# STM32H573 register map
File version: 1.8
CPU: CM33 r0p0, little endian, MPU, FPU, 4 interrupt priority bits
Registers are 32-bit, read-write, reset 0x0 unless marked. A register's access mark holds for its fields unless they carry their own. Offsets are from the block's base; [hi:lo] are bit positions; {n}, {i} and the like mark numbered series; 'fields as' and 'values as' point back to an identical list.

## TIM1 — Advanced-control timers
Base 0x40012C00
Same registers: SEC_TIM1 0x50012C00
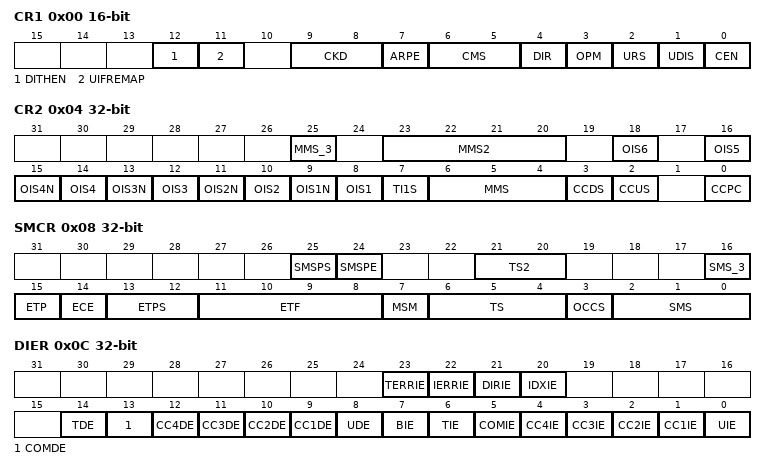
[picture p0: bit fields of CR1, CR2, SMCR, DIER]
0x00 CR1 16-bit — TIM1 control register 1
  [12] DITHEN — Dithering enable Note: The DITHEN bit can only be modified when CEN bit is reset.
    0=Disabled (Dithering disabled); 1=Enabled (Dithering enabled)
  [11] UIFREMAP — UIF status bit remapping
    0=Disabled (No remapping. UIF status bit is not copied to TIMx_CNT register bit 31); 1=Enabled (Remapping enabled. UIF status bit is copied to TIMx_CNT register bit 31)
  [9:8] CKD — Clock division This bit-field indicates the division ratio between the timer clock (tim_ker_ck) frequency and the dead-time and sampling clock (t sub DTS /sub )used by the dead-time generators and the digital filters (tim_etr_in, tim_tix),
    0=Div1 (t_DTS = t_CK_INT); 1=Div2 (t_DTS = 2 × t_CK_INT); 2=Div4 (t_DTS = 4 × t_CK_INT)
  [7] ARPE — Auto-reload preload enable
    0=Disabled (TIMx_APRR register is not buffered); 1=Enabled (TIMx_APRR register is buffered)
  [6:5] CMS — Center-aligned mode selection Note: It is not allowed to switch from edge-aligned mode to center-aligned mode as long as the counter is enabled (CEN=1)
    0=EdgeAligned (The counter counts up or down depending on the direction bit); 1=CenterAligned1 (The counter counts up and down alternatively. Output compare interrupt flags are set only when the counter is counting down.); 2=CenterAligned2 (The counter counts up and down alternatively. Output compare interrupt flags are set only when the counter is counting up.); 3=CenterAligned3 (The counter counts up and down alternatively. Output compare interrupt flags are set both when the counter is counting up or down.)
  [4] DIR — Direction Note: This bit is read only when the timer is configured in Center-aligned mode or Encoder mode.
    0=Up (Counter used as upcounter); 1=Down (Counter used as downcounter)
  [3] OPM — One-pulse mode
    0=Disabled (Counter is not stopped at update event); 1=Enabled (Counter stops counting at the next update event (clearing the CEN bit))
  [2] URS — Update request source This bit is set and cleared by software to select the UEV event sources. Counter overflow/underflow Setting the UG bit Update generation through the slave mode controller
    0=AnyEvent (Any of counter overflow/underflow, setting UG, or update through slave mode, generates an update interrupt or DMA request); 1=CounterOnly (Only counter overflow/underflow generates an update interrupt or DMA request)
  [1] UDIS — Update disable This bit is set and cleared by software to enable/disable UEV event generation. Counter overflow/underflow Setting the UG bit Update generation through the slave mode controller Buffered registers are then loaded with their preload values.
    0=Enabled (Update event enabled); 1=Disabled (Update event disabled)
  [0] CEN — Counter enable Note: External clock, gated mode and encoder mode can work only if the CEN bit has been previously set by software. However trigger mode can set the CEN bit automatically by hardware.
    0=Disabled (Counter disabled); 1=Enabled (Counter enabled)
0x04 CR2 — TIM1 control register 2
  [25] MMS_3
  [23:20] MMS2 — Master mode selection 2 These bits allow the information to be sent to ADC for synchronization (tim_trgo2) to be selected. The combination is as follows: Note: The clock of the slave timer or ADC must be enabled prior to receive events from the master timer, and must not be changed on-the-fly while triggers are received from the master timer.
  [2n+7] OIS{n}N (n=1..4) — Output Idle state (OC{n}N output)
    0=Reset (OCxN=0 after a dead-time when MOE=0); 1=Set (OCxN=1 after a dead-time when MOE=0)
  [2n+6] OIS{n} (n=1..6) — Output Idle state (OC{n} output)
    0=Reset (OCx=0 (after a dead-time if OCx(N) is implemented) when MOE=0); 1=Set (OCx=1 (after a dead-time if OCx(N) is implemented) when MOE=0)
  [7] TI1S — tim_ti1 selection
    0=Normal (The TIMx_CH1 pin is connected to TI1 input); 1=XOR (The TIMx_CH1, CH2, CH3 pins are connected to TI1 input)
  [6:4] MMS — MMS[2:0]: Master mode selection These bits select the information to be sent in master mode to slave timers for synchronization (tim_trgo). The combination is as follows: Other codes reserved Note: The clock of the slave timer or ADC must be enabled prior to receive events from the master timer, and must not be changed on-the-fly while triggers are received from the master timer.
  [3] CCDS — Capture/compare DMA selection
    0=OnCompare (CCx DMA request sent when CCx event occurs); 1=OnUpdate (CCx DMA request sent when update event occurs)
  [2] CCUS — Capture/compare control update selection Note: This bit acts only on channels that have a complementary output.
    0=Sw (When capture/compare control bits are preloaded (CCPC=1), they are updated by setting the COMG bit only); 1=SwOrEdge (When capture/compare control bits are preloaded (CCPC=1), they are updated by setting the COMG bit or when an rising edge occurs on TRGI)
  [0] CCPC — Capture/compare preloaded control Note: This bit acts only on channels that have a complementary output.
    0=NotPreloaded (CCxE, CCxNE and OCxM bits are not preloaded); 1=Preloaded (CCxE, CCxNE and OCxM bits are preloaded)
0x08 SMCR — TIM1 slave mode control register
  [25] SMSPS — SMS preload source This bit selects whether the events that triggers the SMS[3:0] bitfield transfer from preload to active
    0=Update (SMSM[3:0] is preloaded from Update event); 1=Index (SMSM[3:0] is preloaded from Index event)
  [24] SMSPE — SMS preload enable This bit selects whether the SMS[3:0] bitfield is preloaded
    0=NotPreloaded (SMSM[3:0] is not preloaded); 1=PreloadEnabled (SMSM[3:0] is preload is enabled)
  [21:20] TS2 — Trigger selection This bit-field selects the trigger input to be used to synchronize the counter. Others: Reserved See for product specific implementation details. Note: These bits must be changed only when they are not used (e.g. when SMS=000) to avoid wrong edge detections at the transition.
  [16] SMS_3 — Slave mode selection When external signals are selected the active edge of the trigger signal (tim_trgi) is linked to the polarity selected on the external input (see Input Control register and Control Register description. Note: The gated mode must not be used if tim_ti1f_ed is selected as the trigger input (TS=00100). Indeed, tim_ti1f_ed outputs 1 pulse for each transition on tim_ti1f, whereas the gated mode checks the level of the trigger signal. Note: The clock of the slave peripherals (timer, ADC, ...) receiving the tim_trgo signal must be enabled prior to receive events from the master timer, and the clock frequency (prescaler) must not be changed on-the-fly while triggers are received from the master timer.
  [15] ETP — External trigger polarity This bit selects whether tim_etr_in or tim_etr_in is used for trigger operations
    0=NotInverted (ETR is noninverted, active at high level or rising edge); 1=Inverted (ETR is inverted, active at low level or falling edge)
  [14] ECE — External clock enable This bit enables External clock mode 2. Note: Setting the ECE bit has the same effect as selecting external clock mode 1 with tim_trgi connected to tim_etrf (SMS=111 and TS=00111). It is possible to simultaneously use external clock mode 2 with the following slave modes: reset mode, gated mode and trigger mode. Nevertheless, tim_trgi must not be connected to tim_etrf in this case (TS bits must not be 00111). Note: If external clock mode 1 and external clock mode 2 are enabled at the same time, the external clock input is tim_etrf.
    0=Disabled (External clock mode 2 disabled); 1=Enabled (External clock mode 2 enabled. The counter is clocked by any active edge on the ETRF signal.)
  [13:12] ETPS — External trigger prescaler External trigger signal tim_etrp frequency must be at most 1/4 of TIMxCLK frequency. A prescaler can be enabled to reduce tim_etrp frequency. It is useful when inputting fast external clocks on tim_etr_in.
    0=Div1 (Prescaler OFF); 1=Div2 (ETRP frequency divided by 2); 2=Div4 (ETRP frequency divided by 4); 3=Div8 (ETRP frequency divided by 8)
  [11:8] ETF — External trigger filter This bit-field then defines the frequency used to sample tim_etrp signal and the length of the digital filter applied to tim_etrp. The digital filter is made of an event counter in which N consecutive events are needed to validate a transition on the output:
    0=No filter, sampling is done at fDTS; 1=FCK_INT_N2 (fSAMPLING=fCK_INT, N=2); 2=FCK_INT_N4 (fSAMPLING=fCK_INT, N=4); 3=FCK_INT_N8 (fSAMPLING=fCK_INT, N=8); 4=FDTS_Div2_N6 (fSAMPLING=fDTS/2, N=6); 5=FDTS_Div2_N8 (fSAMPLING=fDTS/2, N=8); 6=FDTS_Div4_N6 (fSAMPLING=fDTS/4, N=6); 7=FDTS_Div4_N8 (fSAMPLING=fDTS/4, N=8); 8=FDTS_Div8_N6 (fSAMPLING=fDTS/8, N=6); 9=FDTS_Div8_N8 (fSAMPLING=fDTS/8, N=8); 10=FDTS_Div16_N5 (fSAMPLING=fDTS/16, N=5); 11=FDTS_Div16_N6 (fSAMPLING=fDTS/16, N=6); 12=FDTS_Div16_N8 (fSAMPLING=fDTS/16, N=8); 13=FDTS_Div32_N5 (fSAMPLING=fDTS/32, N=5); 14=FDTS_Div32_N6 (fSAMPLING=fDTS/32, N=6); 15=FDTS_Div32_N8 (fSAMPLING=fDTS/32, N=8)
  [7] MSM — Master/slave mode
    0=NoSync (No action); 1=Sync (The effect of an event on the trigger input (TRGI) is delayed to allow a perfect synchronization between the current timer and its slaves (through TRGO). It is useful if we want to synchronize several timers on a single external event.)
  [6:4] TS — TS[2:0]: Trigger selection This bitfield is combined with TS[4:3] bits. This bit-field selects the trigger input to be used to synchronize the counter. Others: Reserved See Table 605: TIMx internal trigger connection for more details on tim_itrx meaning for each Timer. Note: These bits must be changed only when they are not used (e.g. when SMS=000) to avoid wrong edge detections at the transition.
  [3] OCCS — OCREF clear selection This bit is used to select the OCREF clear source.
  [2:0] SMS — SMS[2:0]: Slave mode selection When external signals are selected the active edge of the trigger signal (tim_trgi) is linked to the polarity selected on the external input (see Input Control register and Control Register description. Note: The gated mode must not be used if tim_ti1f_ed is selected as the trigger input (TS=00100). Indeed, tim_ti1f_ed outputs 1 pulse for each transition on TI1F, whereas the gated mode checks the level of the trigger signal. Note: The clock of the slave peripherals (timer, ADC, ...) receiving the tim_trgo or the tim_trgo2 signals must be enabled prior to receive events from the master timer, and the clock frequency (prescaler) must not be changed on-the-fly while triggers are received from the master timer.
0x0C DIER — TIM1 DMA/interrupt enable register
  [23] TERRIE — Transition error interrupt enable
    0=Disabled (Transition error interrupt disabled); 1=Enabled (Transition error interrupt enabled)
  [22] IERRIE — Index error interrupt enable
    0=Disabled (Index error interrupt disabled); 1=Enabled (Index error interrupt enabled)
  [21] DIRIE — Direction change interrupt enable
    0=Disabled (Direction change interrupt disabled); 1=Enabled (Direction change interrupt enabled)
  [20] IDXIE — Index interrupt enable
    0=Disabled (Index change interrupt disabled); 1=Enabled (Index change interrupt enabled)
  [14] TDE — Trigger DMA request enable
    0=Disabled (Trigger DMA request disabled); 1=Enabled (Trigger DMA request enabled)
  [13] COMDE — COM DMA request enable
    0=Disabled (COM DMA request disabled); 1=Enabled (COM DMA request enabled)
  [n+8] CC{n}DE (n=1..4) — Capture/Compare {n} DMA request enable
    0=Disabled (CCx DMA request disabled); 1=Enabled (CCx DMA request enabled)
  [8] UDE — Update DMA request enable
    0=Disabled (Update DMA request disabled); 1=Enabled (Update DMA request enabled)
  [7] BIE — Break interrupt enable
    0=Disabled (Break interrupt disabled); 1=Enabled (Break interrupt enabled)
  [6] TIE — Trigger interrupt enable
    0=Disabled (Trigger interrupt disabled); 1=Enabled (Trigger interrupt enabled)
  [5] COMIE — COM interrupt enable
    0=Disabled (COM interrupt disabled); 1=Enabled (COM interrupt enabled)
  [n] CC{n}IE (n=1..4) — Capture/Compare {n} interrupt enable
    0=Disabled (CCx interrupt disabled); 1=Enabled (CCx interrupt enabled)
  [0] UIE — Update interrupt enable
    0=Disabled (Update interrupt disabled); 1=Enabled (Update interrupt enabled)
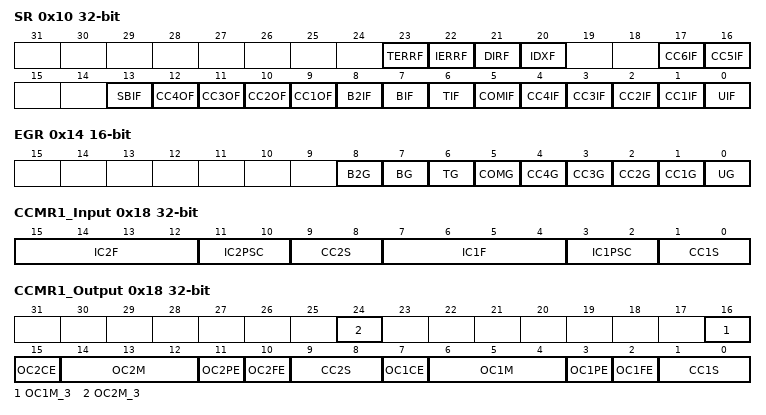
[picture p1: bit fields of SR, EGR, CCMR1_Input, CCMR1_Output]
0x10 SR — TIM1 status register
  [23] TERRF write-0-clears — Transition error interrupt flag This flag is set by hardware when a transition error is detected in encoder mode. It is cleared by software by writing it to '0'.
    on read: 0=NoTrigger (No encoder transition error has been detected); 1=Trigger (An encoder transition error has been detected) | on write: 0=Clear flag
  [22] IERRF write-0-clears — Index error interrupt flag This flag is set by hardware when an index error is detected. It is cleared by software by writing it to '0'.
    on read: 0=NoTrigger (No index error has been detected); 1=Trigger (An index erorr has been detected) | on write: 0=Clear flag
  [21] DIRF write-0-clears — Direction change interrupt flag This flag is set by hardware when the direction changes in encoder mode (DIR bit value in TIMx_CR is changing). It is cleared by software by writing it to '0'.
    on read: 0=NoTrigger (No direction change has been detected); 1=Trigger (A direction change has been detected) | on write: 0=Clear flag
  [20] IDXF write-0-clears — Index interrupt flag This flag is set by hardware when an index event is detected. It is cleared by software by writing it to '0'.
    on read: 0=NoTrigger (No index event occurred); 1=Trigger (An index event has occurred) | on write: 0=Clear flag
  [17] CC6IF write-0-clears — Compare 6 interrupt flag Refer to CC1IF description Note: Channel 6 can only be configured as output.
    on read: 0=NoMatch (No campture/compare has been detected); 1=Match (If CC1 is an output: The content of the counter TIMx_CNT matches the content of the TIMx_CCR1 register. If CC1 is an input: The counter value has been captured in TIMx_CCR1 register.) | on write: 0=Clear flag
  [16] CC5IF write-0-clears — Compare 5 interrupt flag Refer to CC1IF description Note: Channel 5 can only be configured as output.
    values as CC6IF
  [13] SBIF write-0-clears — System break interrupt flag This flag is set by hardware as soon as the system break input goes active. It can be cleared by software if the system break input is not active. This flag must be reset to re-start PWM operation.
    on read: 0=NoTrigger (No break event occurred); 1=Trigger (An active level has been detected on the system break input. An interrupt is generated if BIE=1 in the TIMx_DIER register) | on write: 0=Clear flag
  [n+8] CC{n}OF (n=1..4) write-0-clears — Capture/Compare {n} overcapture flag
    on read: 0=No overcapture has been detected; 1=Overcapture (The counter value has been captured in TIMx_CCRx register while CCxIF flag was already set) | on write: 0=Clear flag
  [8] B2IF write-0-clears — Break 2 interrupt flag This flag is set by hardware as soon as the break 2 input goes active. It can be cleared by software if the break 2 input is not active.
    on read: 0=NoTrigger (No break event occurred); 1=Trigger (An active level has been detected on the break 2 input. An interrupt is generated if BIE=1 in the TIMx_DIER register) | on write: 0=Clear flag
  [7] BIF write-0-clears — Break interrupt flag This flag is set by hardware as soon as the break input goes active. It can be cleared by software if the break input is not active.
    on read: 0=NoTrigger (No break event occurred); 1=Trigger (An active level has been detected on the break input. An interrupt is generated if BIE=1 in the TIMx_DIER register) | on write: 0=Clear flag
  [6] TIF write-0-clears — Trigger interrupt flag This flag is set by hardware on the TRG trigger event (active edge detected on tim_trgi input when the slave mode controller is enabled in all modes but gated mode. It is set when the counter starts or stops when gated mode is selected. It is cleared by software.
    on read: 0=No trigger event occurred; 1=Trigger interrupt pending | on write: 0=Clear flag
  [5] COMIF write-0-clears — COM interrupt flag This flag is set by hardware on COM event (when capture/compare Control bits CCxE, CCxNE, OCxM have been updated). It is cleared by software.
    on read: 0=No COM event occurred; 1=COM (COM interrupt pending) | on write: 0=Clear flag
  [n] CC{n}IF (n=1..4) write-0-clears — Capture/compare {n} interrupt flag
    values as CC6IF
  [0] UIF write-0-clears — Update interrupt flag This bit is set by hardware on an update event. It is cleared by software. At overflow or underflow regarding the repetition counter value (update if repetition counter = 0) and if the UDIS=0 in the TIMx_CR1 register. When CNT is reinitialized by software using the UG bit in TIMx_EGR register, if URS=0 and UDIS=0 in the TIMx_CR1 register. When CNT is reinitialized by a trigger event (refer to Section 65.6.3: TIM1 slave mode control register (TIM1_SMCR)), if URS=0 and UDIS=0 in the TIMx_CR1 register.
    on read: 0=NoUpdateOccurred; 1=UpdatePending (Update interrupt pending) | on write: 0=Clear flag
0x14 EGR 16-bit wo — TIM1 event generation register
  [8] B2G — Break 2 generation This bit is set by software in order to generate an event, it is automatically cleared by hardware.
    1=Trigger (A break 2 event is generated. MOE bit is cleared and B2IF flag is set. Related interrupt can occur if enabled)
  [7] BG — Break generation This bit is set by software in order to generate an event, it is automatically cleared by hardware.
    1=Trigger (A break event is generated. MOE bit is cleared and BIF flag is set. Related interrupt or DMA transfer can occur if enabled)
  [6] TG — Trigger generation This bit is set by software in order to generate an event, it is automatically cleared by hardware.
    1=Trigger (The TIF flag is set in TIMx_SR register. Related interrupt or DMA transfer can occur if enabled.)
  [5] COMG — Capture/compare control update generation This bit can be set by software, it is automatically cleared by hardware Note: This bit acts only on channels having a complementary output.
    1=Trigger (When CCPC bit is set, it allows CCxE, CCxNE and OCxM bits to be updated)
  [n] CC{n}G (n=1..4) — Capture/compare {n} generation
    1=Trigger (If CC1 is an output: CC1IF flag is set, Corresponding interrupt or DMA request is sent if enabled. If CC1 is an input: The current value of the counter is captured in TIMx_CCR1 register.)
  [0] UG — Update generation This bit can be set by software, it is automatically cleared by hardware.
    1=Update (Re-initializes the timer counter and generates an update of the registers.)
0x18 CCMR1_Input — TIM1 capture/compare mode register 1 [alternate]
  [9:8] CC2S — Capture/compare 2 selection This bit-field defines the direction of the channel (input/output) as well as the used input. Note: CC2S bits are writable only when the channel is OFF (CC2E = '0' in TIMx_CCER).
    1=TI2 (CC2 channel is configured as input, IC2 is mapped on TI2); 2=TI1 (CC2 channel is configured as input, IC2 is mapped on TI1); 3=TRC (CC2 channel is configured as input, IC2 is mapped on TRC)
  [8n-1:8n-4] IC{n}F (n=1..2) — Input capture {n} filter
    values as SMCR.ETF
  [8n-5:8n-6] IC{n}PSC (n=1..2) — Input capture {n} prescaler
    0=No prescaler, capture is done each time an edge is detected on the capture input; 1=TwoEvents (Capture is done once every 2 events); 2=FourEvents (Capture is done once every 4 events); 3=EightEvents (Capture is done once every 8 events)
  [1:0] CC1S — Capture/compare 1 Selection This bit-field defines the direction of the channel (input/output) as well as the used input. Note: CC1S bits are writable only when the channel is OFF (CC1E = '0' in TIMx_CCER).
    1=TI1 (CC1 channel is configured as input, IC1 is mapped on TI1); 2=TI2 (CC1 channel is configured as input, IC1 is mapped on TI2); 3=TRC (CC1 channel is configured as input, IC1 is mapped on TRC)
0x18 CCMR1_Output (alternate view of CCMR1_Input) — TIM1 capture/compare mode register 1 [alternate]
  [8n+8] OC{n}M_3 (n=1..2) — Output compare {n} mode, bit 3
    0=Normal output compare mode (modes 0-7); 1=Extended output compare mode (modes 7-15)
  [8n-1] OC{n}CE (n=1..2) — Output compare {n} clear enable
    0=Disabled (OCxRef is not affected by the ocref_clr_int signal); 1=Enabled (OCxRef is cleared as soon as a High level is detected on ocref_clr_int signal)
  [8n-2:8n-4] OC{n}M (n=1..2) — Output compare {n} mode
    0=Frozen (The comparison between the output compare register TIMx_CCRy and the counter TIMx_CNT has no effect on the outputs / OpmMode1: Retriggerable OPM mode 1 - In up-counting mode, the channel is active until a trigger event is detected (on TRGI signal). In down-counting mode, the channel is inactive); 1=ActiveOnMatch (Set channel to active level on match. OCyREF signal is forced high when the counter matches the capture/compare register / OpmMode2: Inversely to OpmMode1); 2=InactiveOnMatch (Set channel to inactive level on match. OCyREF signal is forced low when the counter matches the capture/compare register / Reserved); 3=Toggle (OCyREF toggles when TIMx_CNT=TIMx_CCRy / Reserved); 4=ForceInactive (OCyREF is forced low / CombinedPwmMode1: OCyREF has the same behavior as in PWM mode 1. OCyREFC is the logical OR between OC1REF and OC2REF); 5=ForceActive (OCyREF is forced high / CombinedPwmMode2: OCyREF has the same behavior as in PWM mode 2. OCyREFC is the logical AND between OC1REF and OC2REF); 6=PwmMode1 (In upcounting, channel is active as long as TIMx_CNT<TIMx_CCRy else inactive. In downcounting, channel is inactive as long as TIMx_CNT>TIMx_CCRy else active / AsymmetricPwmMode1: OCyREF has the same behavior as in PWM mode 1. OCyREFC outputs OC1REF when the counter is counting up, OC2REF when it is counting down); 7=PwmMode2 (Inversely to PwmMode1 / AsymmetricPwmMode2: Inversely to AsymmetricPwmMode1)
  [8n-5] OC{n}PE (n=1..2) — Output compare {n} preload enable
    0=Disabled (Preload register on CCRx disabled. New values written to CCRx are taken into account immediately); 1=Enabled (Preload register on CCRx enabled. Preload value is loaded into active register on each update event)
  [8n-6] OC{n}FE (n=1..2) — Output compare {n} fast enable
    0=Disabled (Fast output disabled); 1=Enabled (Fast output enabled)
  [8n-7:8n-8] CC{n}S (n=1..2) — Capture/Compare {n} selection
    0=Output (CCx channel is configured as output)
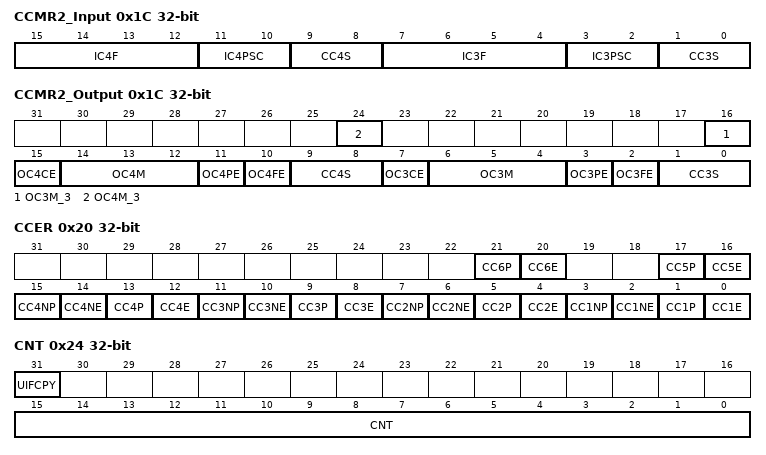
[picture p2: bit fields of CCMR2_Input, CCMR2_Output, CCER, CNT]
0x1C CCMR2_Input — TIM1 capture/compare mode register 2 [alternate]
  [9:8] CC4S — Capture/compare 4 selection This bit-field defines the direction of the channel (input/output) as well as the used input. Note: CC4S bits are writable only when the channel is OFF (CC4E = '0' in TIMx_CCER).
    1=TI4 (CC4 channel is configured as input, IC4 is mapped on TI4); 2=TI3 (CC4 channel is configured as input, IC4 is mapped on TI3); 3=TRC (CC4 channel is configured as input, IC4 is mapped on TRC)
  [8n-17:8n-20] IC{n}F (n=3..4) — Input capture {n} filter
    values as SMCR.ETF
  [8n-21:8n-22] IC{n}PSC (n=3..4) — Input capture {n} prescaler
    values as CCMR1_Input.IC1PSC
  [1:0] CC3S — Capture/compare 3 selection This bit-field defines the direction of the channel (input/output) as well as the used input. Note: CC3S bits are writable only when the channel is OFF (CC3E = '0' in TIMx_CCER).
    1=TI3 (CC3 channel is configured as input, IC3 is mapped on TI3); 2=TI4 (CC3 channel is configured as input, IC3 is mapped on TI4); 3=TRC (CC3 channel is configured as input, IC3 is mapped on TRC)
0x1C CCMR2_Output (alternate view of CCMR2_Input) — TIM1 capture/compare mode register 2 [alternate]
  [8n-8] OC{n}M_3 (n=3..4) — Output compare {n} mode, bit 3
    values as CCMR1_Output.OC1M_3
  [8n-17] OC{n}CE (n=3..4) — Output compare {n} clear enable
    values as CCMR1_Output.OC1CE
  [8n-18:8n-20] OC{n}M (n=3..4) — Output compare {n} mode
    values as CCMR1_Output.OC1M
  [8n-21] OC{n}PE (n=3..4) — Output compare {n} preload enable
    values as CCMR1_Output.OC1PE
  [8n-22] OC{n}FE (n=3..4) — Output compare {n} fast enable
    values as CCMR1_Output.OC1FE
  [8n-23:8n-24] CC{n}S (n=3..4) — Capture/Compare {n} selection
    0=Output (CCx channel is configured as output)
0x20 CCER — TIM1 capture/compare enable register
  [4n-1] CC{n}NP (n=1..4) — Capture/Compare {n} output Polarity
    0=ActiveHigh (OCxN active high); 1=ActiveLow (OCxN active low)
  [4n-2] CC{n}NE (n=1..4) — Capture/Compare {n} complementary output enable
    0=Disabled (Complementary output disabled); 1=Enabled (Complementary output enabled)
  [4n-3] CC{n}P (n=1..6) — Capture/Compare {n} output Polarity
    0=RisingEdge (Noninverted/rising edge); 1=FallingEdge (Inverted/falling edge)
  [4n-4] CC{n}E (n=1..6) — Capture/Compare {n} output enable
    0=Disabled (Capture disabled); 1=Enabled (Capture enabled)
0x24 CNT access per field — TIM1 counter
  [31] UIFCPY ro — UIF copy This bit is a read-only copy of the UIF bit of the TIMx_ISR register. If the UIFREMAP bit in the TIMxCR1 is reset, bit 31 is reserved and read at 0.
    0=NoUpdateOccurred; 1=UpdatePending (Update interrupt pending)
  [15:0] CNT rw — Counter value Non-dithering mode (DITHEN = 0) The register holds the counter value. Dithering mode (DITHEN = 1) The register only holds the non-dithered part in CNT[15:0]. The fractional part is not available.
0x28 PSC 16-bit — TIM1 prescaler
  [15:0] PSC — Prescaler value The counter clock frequency (f sub tim_cnt_ck /sub ) is equal to f sub tim_psc_ck /sub / (PSC[15:0] + 1). PSC contains the value to be loaded in the active prescaler register at each update event (including when the counter is cleared through UG bit of TIMx_EGR register or through trigger controller when configured in 'reset mode').
0x2C ARR reset 0xFFFF — TIM1 auto-reload register
  [19:0] ARR — Auto-reload value ARR is the value to be loaded in the actual auto-reload register. Refer to the Section 65.3.3: Time-base unit on page 4457 for more details about ARR update and behavior. The counter is blocked while the auto-reload value is null. Non-dithering mode (DITHEN = 0) The register holds the auto-reload value. Dithering mode (DITHEN = 1) The register holds the integer part in ARR[19:4]. The ARR[3:0] bitfield contains the dithered part.
0x30 RCR 16-bit — TIM1 repetition counter register
  [15:0] REP — Repetition counter reload value This bitfield defines the update rate of the compare registers (i.e. periodic transfers from preload to active registers) when preload registers are enable. It also defines the update interrupt generation rate, if this interrupt is enable. When the repetition down-counter reaches zero, an update event is generated and it restarts counting from REP value. As the repetition counter is reloaded with REP value only at the repetition update event UEV, any write to the TIMx_RCR register is not taken in account until the next repetition update event. It means in PWM mode (REP+1) corresponds to: the number of PWM periods in edge-aligned mode the number of half PWM period in center-aligned mode.
{0x30+4i} CCR{i} (i=1..4) — capture/compare register
  [19:0] CCR — Capture/Compare value
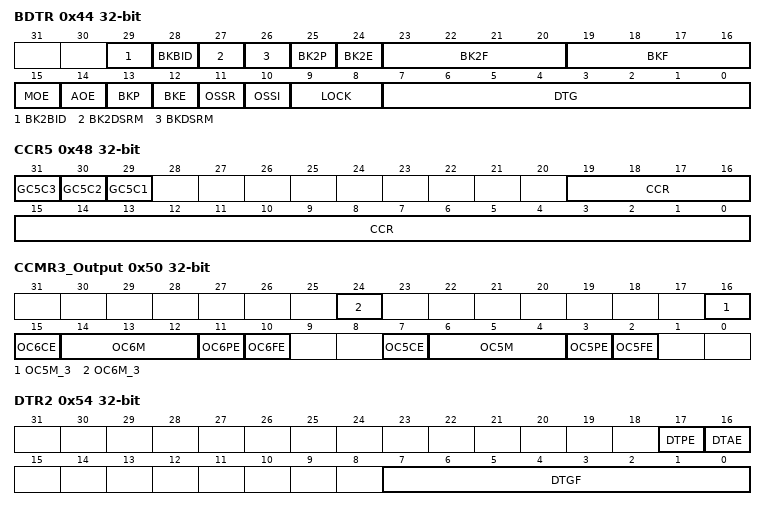
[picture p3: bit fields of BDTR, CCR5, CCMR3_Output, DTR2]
0x44 BDTR — TIM1 break and dead-time register
  [29] BK2BID — Break2 bidirectional Refer to BKBID description
    0=Input (Break input BRK2 in input mode); 1=Bidirectional (Break input BRK2 in bidirectional mode)
  [28] BKBID — Break bidirectional In the bidirectional mode (BKBID bit set to 1), the break input is configured both in input mode and in open drain output mode. Any active break event asserts a low logic level on the Break input to indicate an internal break event to external devices. Note: This bit cannot be modified as long as LOCK level 1 has been programmed (LOCK bits in TIMx_BDTR register). Note: Any write operation to this bit takes a delay of 1 APB clock cycle to become effective.
    0=Input (Break input BRK in input mode); 1=Bidirectional (Break input BRK in bidirectional mode)
  [27] BK2DSRM — Break2 disarm Refer to BKDSRM description
    0=Armed (Break input BRK2 is armed); 1=Disarmed (Break input BRK2 is disarmed)
  [26] BKDSRM — Break disarm This bit is cleared by hardware when no break source is active. The BKDSRM bit must be set by software to release the bidirectional output control (open-drain output in Hi-Z state) and then be polled it until it is reset by hardware, indicating that the fault condition has disappeared. Note: Any write operation to this bit takes a delay of 1 APB clock cycle to become effective.
    0=Armed (Break input BRK is armed); 1=Disarmed (Break input BRK is disarmed)
  [25] BK2P — Break 2 polarity Note: This bit cannot be modified as long as LOCK level 1 has been programmed (LOCK bits in TIMx_BDTR register). Note: Any write operation to this bit takes a delay of 1 APB clock cycle to become effective.
    0=ActiveLow (Break input BRKx is active low); 1=ActiveHigh (Break input BRKx is active high)
  [24] BK2E — Break 2 enable This bit enables the complete break 2 protection (including all sources connected to bk_acth and BKIN sources, as per Figure 635: Break and Break2 circuitry overview). Note: The BRKIN2 must only be used with OSSR = OSSI = 1. Note: This bit cannot be modified when LOCK level 1 has been programmed (LOCK bits in TIMx_BDTR register). Note: Any write operation to this bit takes a delay of 1 APB clock cycle to become effective.
    0=Disabled (Break function x disabled); 1=Enabled (Break function x enabled)
  [23:20] BK2F — Break 2 filter This bit-field defines the frequency used to sample tim_brk2 input and the length of the digital filter applied to tim_brk2. The digital filter is made of an event counter in which N consecutive events are needed to validate a transition on the output: Note: This bit cannot be modified when LOCK level 1 has been programmed (LOCK bits in TIMx_BDTR register).
    values as SMCR.ETF
  [19:16] BKF — Break filter This bit-field defines the frequency used to sample tim_brk input and the length of the digital filter applied to tim_brk. The digital filter is made of an event counter in which N consecutive events are needed to validate a transition on the output: Note: This bit cannot be modified when LOCK level 1 has been programmed (LOCK bits in TIMx_BDTR register).
    values as SMCR.ETF
  [15] MOE — Main output enable This bit is cleared asynchronously by hardware as soon as one of the break inputs is active (tim_brk or tim_brk2). It is set by software or automatically depending on the AOE bit. It is acting only on the channels which are configured in output. In response to a break event or if MOE is written to 0: OC and OCN outputs are disabled or forced to idle state depending on the OSSI bit. See OC/OCN enable description for more details (Section 65.6.11: TIM1 capture/compare enable register (TIM1_CCER)).
    0=DisabledIdle (OC/OCN are disabled or forced idle depending on OSSI); 1=Enabled (OC/OCN are enabled if CCxE/CCxNE are set)
  [14] AOE — Automatic output enable Note: This bit can not be modified as long as LOCK level 1 has been programmed (LOCK bits in TIMx_BDTR register).
    0=Manual (MOE can be set only by software); 1=Automatic (MOE can be set by software or automatically at the next update event (if none of the break inputs BRK and BRK2 is active))
  [13] BKP — Break polarity Note: This bit can not be modified as long as LOCK level 1 has been programmed (LOCK bits in TIMx_BDTR register). Note: Any write operation to this bit takes a delay of 1 APB clock cycle to become effective.
    values as BK2P
  [12] BKE — Break enable This bit enables the complete break protection (including all sources connected to bk_acth and BKIN sources, as per Figure 635: Break and Break2 circuitry overview). Note: This bit cannot be modified when LOCK level 1 has been programmed (LOCK bits in TIMx_BDTR register). Note: Any write operation to this bit takes a delay of 1 APB clock cycle to become effective.
    values as BK2E
  [11] OSSR — Off-state selection for Run mode This bit is used when MOE=1 on channels having a complementary output which are configured as outputs. OSSR is not implemented if no complementary output is implemented in the timer. See OC/OCN enable description for more details (Section 65.6.11: TIM1 capture/compare enable register (TIM1_CCER)). Note: This bit can not be modified as soon as the LOCK level 2 has been programmed (LOCK bits in TIMx_BDTR register).
    0=HiZ (When inactive, OC/OCN outputs are disabled); 1=IdleLevel (When inactive, OC/OCN outputs are enabled with their inactive level)
  [10] OSSI — Off-state selection for idle mode This bit is used when MOE=0 due to a break event or by a software write, on channels configured as outputs. See OC/OCN enable description for more details (Section 65.6.11: TIM1 capture/compare enable register (TIM1_CCER)). Note: This bit can not be modified as soon as the LOCK level 2 has been programmed (LOCK bits in TIMx_BDTR register).
    0=HiZ (When inactive, OC/OCN outputs are disabled); 1=IdleLevel (When inactive, OC/OCN outputs are forced to idle level)
  [9:8] LOCK — Lock configuration These bits offer a write protection against software errors. Note: The LOCK bits can be written only once after the reset. Once the TIMx_BDTR register has been written, their content is frozen until the next reset.
    0=Off (No bit is write protected); 1=Level1 (Any bits except MOE, OSSR, OSSI and LOCK in TIMx_BDTR register, OISx and OISxN bits in TIMx_CR2 register can no longer be written); 2=Level2 (LOCK Level 1 + CC Polarity bits (CCxP/CCxNP bits in TIMx_CCER register, as long as the related channel is configured in output through the CCxS bits) as well as OSSR and OSSI bits can no longer be written); 3=Level3 (LOCK Level 2 + CC Control bits (OCxM and OCxPE bits in TIMx_CCMRx registers, as long as the related channel is configured in output through the CCxS bits) can no longer be written)
  [7:0] DTG — Dead-time generator setup This bit-field defines the duration of the dead-time inserted between the complementary outputs. DT correspond to this duration. DTG[7:5]=0xx = DT=DTG[7:0]x t sub dtg /sub with t sub dtg /sub =t sub DTS /sub . DTG[7:5]=10x = DT=(64+DTG[5:0])xt sub dtg /sub with T sub dtg /sub =2xt sub DTS /sub . DTG[7:5]=110 = DT=(32+DTG[4:0])xt sub dtg /sub with T sub dtg /sub =8xt sub DTS /sub . DTG[7:5]=111 = DT=(32+DTG[4:0])xt sub dtg /sub with T sub dtg /sub =16xt sub DTS /sub . Example if T sub DTS /sub =125ns (8MHz), dead-time possible values are: 0 to 15875 ns by 125 ns steps, 16 us to 31750 ns by 250 ns steps, 32 us to 63us by 1 us steps, 64 us to 126 us by 2 us steps Note: This bit-field can not be modified as long as LOCK level 1, 2 or 3 has been programmed (LOCK bits in TIMx_BDTR register).
0x48 CCR5 — capture/compare register
  [31] GC5C3 — Group channel 5 and channel 3 Distortion on channel 3 output: This bit can either have immediate effect or be preloaded and taken into account after an update event (if preload feature is selected in TIMxCCMR2). Note: it is also possible to apply this distortion on combined PWM signals.
  [30] GC5C2 — Group channel 5 and channel 2 Distortion on channel 2 output: This bit can either have immediate effect or be preloaded and taken into account after an update event (if preload feature is selected in TIMxCCMR1). Note: it is also possible to apply this distortion on combined PWM signals.
  [29] GC5C1 — Group channel 5 and channel 1 Distortion on channel 1 output: This bit can either have immediate effect or be preloaded and taken into account after an update event (if preload feature is selected in TIMxCCMR1). Note: it is also possible to apply this distortion on combined PWM signals.
  [19:0] CCR — Capture/Compare value
0x4C CCR6 — capture/compare register
  [19:0] CCR — Capture/Compare value
0x50 CCMR3_Output — TIM1 capture/compare mode register 3
  [8n-24] OC{n}M_3 (n=5..6) — Output compare {n} mode, bit 3
    values as CCMR1_Output.OC1M_3
  [8n-33] OC{n}CE (n=5..6) — Output compare {n} clear enable
    values as CCMR1_Output.OC1CE
  [8n-34:8n-36] OC{n}M (n=5..6) — Output compare {n} mode
    values as CCMR1_Output.OC1M
  [8n-37] OC{n}PE (n=5..6) — Output compare {n} preload enable
    values as CCMR1_Output.OC1PE
  [8n-38] OC{n}FE (n=5..6) — Output compare {n} fast enable
    values as CCMR1_Output.OC1FE
0x54 DTR2 — TIM1 timer deadtime register 2
  [17] DTPE — Deadtime preload enable Note: This bit can not be modified as long as LOCK level 1, 2 or 3 has been programmed (LOCK bits in TIMx_BDTR register).
  [16] DTAE — Deadtime asymmetric enable Note: This bit can not be modified as long as LOCK level 1, 2 or 3 has been programmed (LOCK bits in TIMx_BDTR register).
  [7:0] DTGF — Dead-time falling edge generator setup This bit-field defines the duration of the dead-time inserted between the complementary outputs, on the falling edge. DTGF[7:5]=0xx = DTF=DTGF[7:0]x t sub dtg /sub with t sub dtg /sub =t sub DTS /sub . DTGF[7:5]=10x = DTF=(64+DTGF[5:0])xt sub dtg /sub with T sub dtg /sub =2xt sub DTS /sub . DTGF[7:5]=110 = DTF=(32+DTGF[4:0])xt sub dtg /sub with T sub dtg /sub =8xt sub DTS /sub . DTGF[7:5]=111 = DTF=(32+DTGF[4:0])xt sub dtg /sub with T sub dtg /sub =16xt sub DTS /sub . Example if T sub DTS /sub =125ns (8MHz), dead-time possible values are: 0 to 15875 ns by 125 ns steps, 16 us to 31750 ns by 250 ns steps, 32 us to 63us by 1 us steps, 64 us to 126 us by 2 us steps Note: This bit-field can not be modified as long as LOCK level 1, 2 or 3 has been programmed (LOCK bits in TIMx_BDTR register).
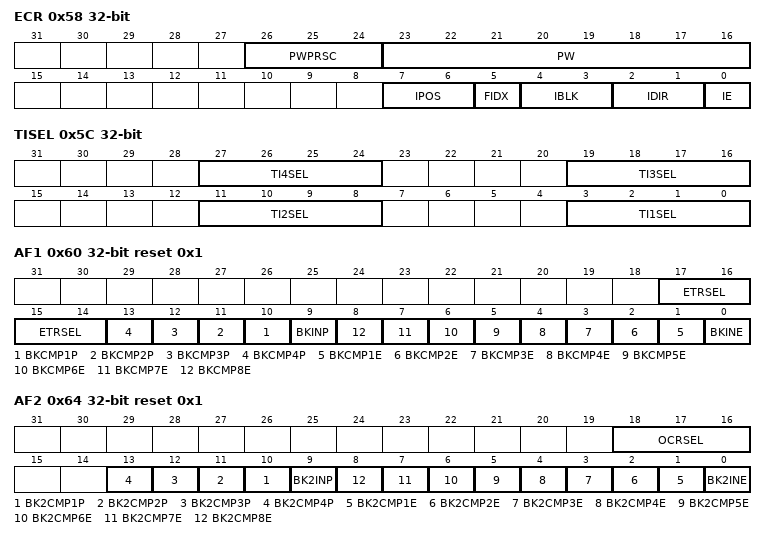
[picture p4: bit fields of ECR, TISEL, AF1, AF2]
0x58 ECR — TIM1 timer encoder control register
  [26:24] PWPRSC — Pulse width prescaler This bitfield sets the clock prescaler for the pulse generator, as following: t sub PWG /sub = (2 sup (PWPRSC[2:0]) /sup ) x t sub tim_ker_ck /sub
  [23:16] PW — Pulse width This bitfield defines the pulse duration, as following: t sub PW /sub = PW[7:0] x t sub PWG /sub
  [7:6] IPOS — Index positioning In quadrature encoder mode (SMS[3:0] = 0001, 0010, 0011, 1110, 1111), this bit indicates in which AB input configuration the Index event resets the counter. In directional clock mode or clock plus direction mode (SMS[3:0] = 1010, 1011, 1100, 1101), these bits indicates on which level the Index event resets the counter. In bidirectional clock mode, this applies for both clock inputs. x0: Index resets the counter when clock is 0 x1: Index resets the counter when clock is 1 Note: IPOS[1] bit is not significant
  [5] FIDX — First index This bit indicates if the first index only is taken into account
  [4:3] IBLK — Index blanking This bit indicates if the Index event is conditioned by the tim_ti3 input
  [2:1] IDIR — Index direction This bit indicates in which direction the Index event resets the counter. Note: The IDR[1:0] bitfield must be written when IE bit is reset (index disabled).
  [0] IE — Index enable This bit indicates if the Index event resets the counter.
0x5C TISEL — TIM1 timer input selection register
  [all] fields
    0=Selected (TIM1_CHx input selected)
  [8n-5:8n-8] TI{n}SEL (n=1..4) — Selects tim_ti{n}[0..15] input ... Refer to Section 65.3.2: TIM1 pins and internal signals for interconnects list.
0x60 AF1 reset 0x1 — TIM1 alternate function option register 1
  [17:14] ETRSEL — etr_in source selection These bits select the etr_in input source. ... Refer to Section 65.3.2: TIM1 pins and internal signals for product specific implementation. Note: These bits can not be modified as long as LOCK level 1 has been programmed (LOCK bits in TIMx_BDTR register).
    0=Legacy (ETR legacy mode); 1=COMP1 (COMP1 output); 2=COMP2 (COMP2 output)
  [n+9] BKCMP{n}P (n=1..4) — tim_brk_cmp{n} input polarity This bit selects the tim_brk_cmp{n} input sensitivity. It must be programmed together with the BKP polarity bit. Note: This bit can not be modified as long as LOCK level 1 has been programmed (LOCK bits in TIMx_BDTR register).
    0=NotInverted (Input polarity not inverted); 1=Inverted (Input polarity inverted)
  [9] BKINP — TIMx_BKIN input polarity This bit selects the TIMx_BKIN alternate function input sensitivity. It must be programmed together with the BKP polarity bit. Note: This bit can not be modified as long as LOCK level 1 has been programmed (LOCK bits in TIMx_BDTR register).
    values as BKCMP1P
  [n] BKCMP{n}E (n=1..8) — tim_brk_cmp{n} enable This bit enables the tim_brk_cmp{n} for the timer's tim_brk input. tim_brk_cmp{n} output is 'ORed' with the other tim_brk sources. Note: This bit can not be modified as long as LOCK level 1 has been programmed (LOCK bits in TIMx_BDTR register).
    0=Disabled (Input disabled); 1=Enabled (Input enabled)
  [0] BKINE — TIMx_BKIN input enable This bit enables the TIMx_BKIN alternate function input for the timer's tim_brk input. TIMx_BKIN input is 'ORed' with the other tim_brk sources. Note: This bit can not be modified as long as LOCK level 1 has been programmed (LOCK bits in TIMx_BDTR register).
    0=Disabled (BKIN input disabled); 1=Enabled (BKIN input enabled)
0x64 AF2 reset 0x1 — TIM1 alternate function register 2
  [18:16] OCRSEL — ocref_clr source selection These bits select the ocref_clr input source. ... Refer to Section 65.3.2: TIM1 pins and internal signals for product specific information. Note: These bits can not be modified as long as LOCK level 1 has been programmed (LOCK bits in TIMx_BDTR register).
  [n+9] BK2CMP{n}P (n=1..4) — tim_brk2_cmp{n} input polarity This bit selects the tim_brk2_cmp{n} input sensitivity. It must be programmed together with the BK2P polarity bit. Note: This bit can not be modified as long as LOCK level 1 has been programmed (LOCK bits in TIMx_BDTR register).
    values as AF1.BKCMP1P
  [9] BK2INP — TIMx_BKIN2 input polarity This bit selects the TIMx_BKIN2 alternate function input sensitivity. It must be programmed together with the BK2P polarity bit. Note: This bit can not be modified as long as LOCK level 1 has been programmed (LOCK bits in TIMx_BDTR register).
    values as AF1.BKCMP1P
  [n] BK2CMP{n}E (n=1..8) — tim_brk2_cmp{n} enable This bit enables the tim_brk2_cmp{n} for the timer's tim_brk2 input. tim_brk2_cmp{n} output is 'ORed' with the other tim_brk2 sources. Note: This bit can not be modified as long as LOCK level 1 has been programmed (LOCK bits in TIMx_BDTR register).
    0=Disabled (Input disabled); 1=Enabled (Input enabled)
  [0] BK2INE — TIMx_BKIN2 input enable This bit enables the TIMx_BKIN2 alternate function input for the timer's tim_brk2 input. TIMx_BKIN2 input is 'ORed' with the other tim_brk2 sources. Note: This bit can not be modified as long as LOCK level 1 has been programmed (LOCK bits in TIMx_BDTR register).
    values as AF1.BKINE
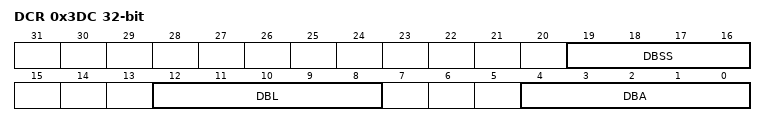
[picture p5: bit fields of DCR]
0x3DC DCR — TIM1 DMA control register
  [19:16] DBSS range 0..7 — DMA burst source selection This bitfield defines the interrupt source that triggers the DMA burst transfers (the timer recognizes a burst transfer when a read or a write access is done to the TIMx_DMAR address). Others: reserved
  [12:8] DBL range 0..18 — DMA burst length This 5-bit vector defines the length of DMA transfers (the timer recognizes a burst transfer when a read or a write access is done to the TIMx_DMAR address), i.e. the number of transfers. Transfers can be in half-words or in bytes (see example below). ... Example: Let us consider the following transfer: DBL = 7 bytes & DBA = TIM2_CR1. If DBL = 7 bytes and DBA = TIM2_CR1 represents the address of the byte to be transferred, the address of the transfer should be given by the following equation: (TIMx_CR1 address) + DBA + (DMA index), where DMA index = DBL In this example, 7 bytes are added to (TIMx_CR1 address) + DBA, which gives us the address from/to which the data are copied. In this case, the transfer is done to 7 registers starting from the following address: (TIMx_CR1 address) + DBA According to the configuration of the DMA Data Size, several cases may occur: If the DMA Data Size is configured in half-words, 16-bit data are transferred to each of the 7 registers. If the DMA Data Size is configured in bytes, the data are also transferred to 7 registers: the first register contains the first MSB byte, the second register, the first LSB byte and so on. So with the transfer Timer, one also has to specify the size of data transferred by DMA.
  [4:0] DBA — DMA base address This 5-bits vector defines the base-address for DMA transfers (when read/write access are done through the TIMx_DMAR address). DBA is defined as an offset starting from the address of the TIMx_CR1 register. Example: ...
0x3E0 DMAR — TIM1 DMA address for full transfer
  [31:0] DMAB range 0..65535 — DMA register for burst accesses A read or write operation to the DMAR register accesses the register located at the address (TIMx_CR1 address) + (DBA + DMA index) x 4 where TIMx_CR1 address is the address of the control register 1, DBA is the DMA base address configured in TIMx_DCR register, DMA index is automatically controlled by the DMA transfer, and ranges from 0 to DBL (DBL configured in TIMx_DCR).

## TIM8 — Advanced-control timers
Base 0x40013400
Same registers: SEC_TIM8 0x50013400
Registers as TIM1 (with TIM1 read as TIM8); these are added or differ:
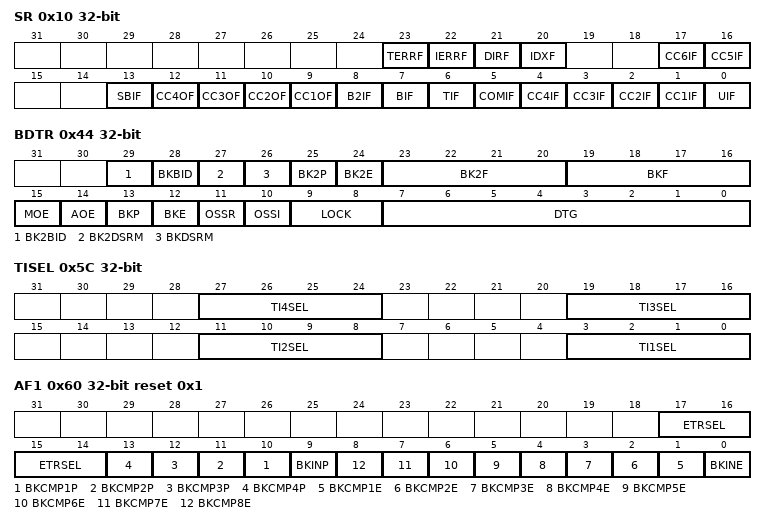
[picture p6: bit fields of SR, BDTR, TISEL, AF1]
0x10 SR — TIM8 status register
  fields as TIM1.SR
0x44 BDTR — TIM8 break and dead-time register
  fields as TIM1.BDTR
0x5C TISEL — TIM8 timer input selection register
  fields as TIM1.TISEL
0x60 AF1 reset 0x1 — TIM8 alternate function option register 1
  fields as TIM1.AF1
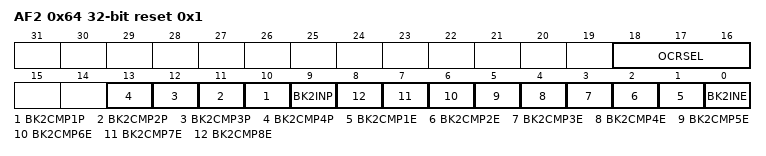
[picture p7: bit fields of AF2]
0x64 AF2 reset 0x1 — TIM8 alternate function register 2
  fields as TIM1.AF2
